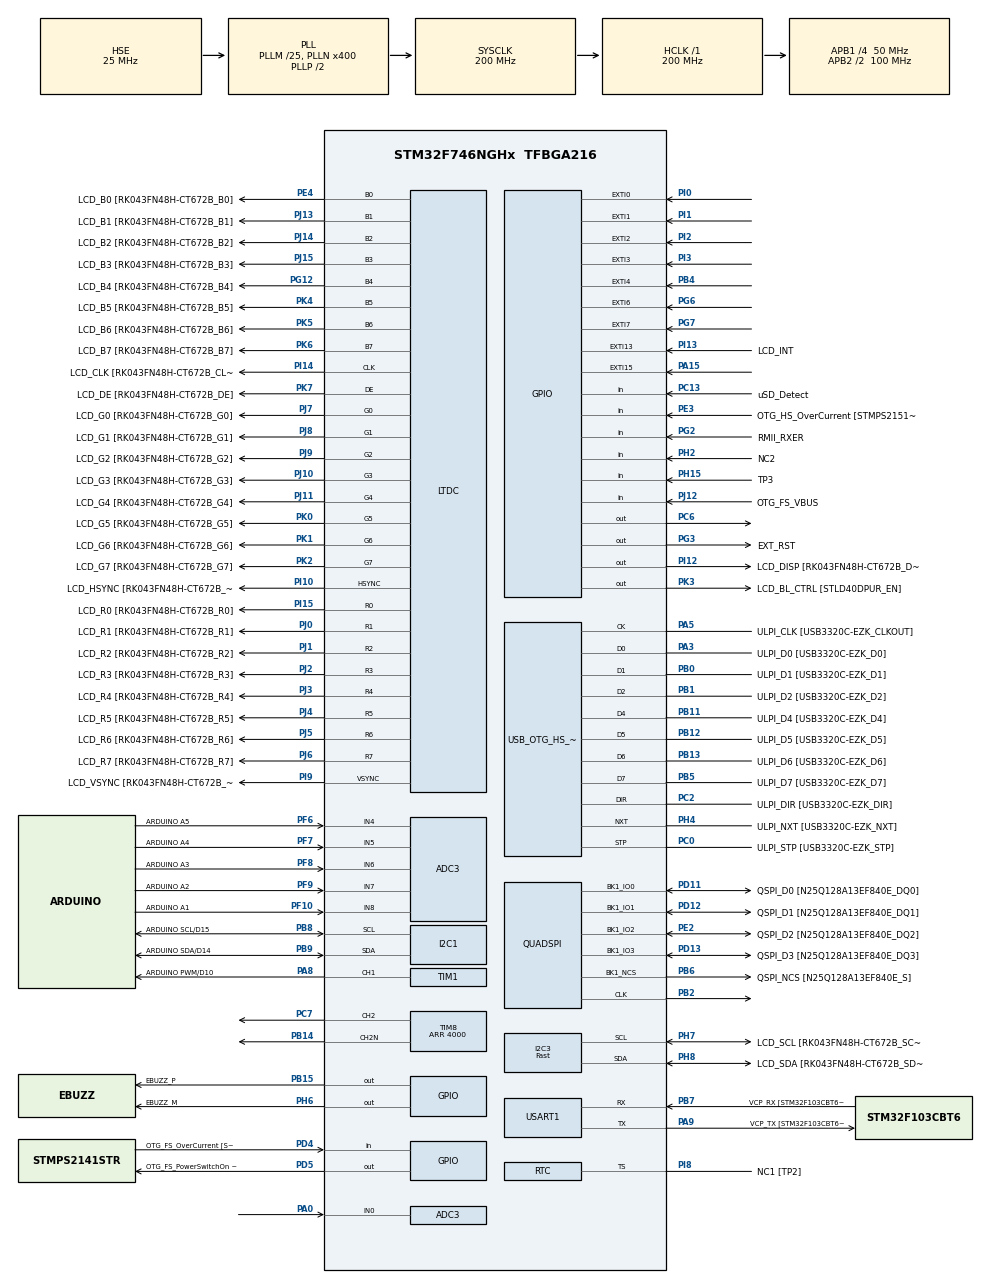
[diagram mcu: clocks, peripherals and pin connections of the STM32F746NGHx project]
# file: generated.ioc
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VP_TIM5_VS_ClockSourceINT.Mode=Internal
Dma.ADC3.0.FIFOMode=DMA_FIFOMODE_DISABLE
PD12.GPIO_Label=QSPI_D1 [N25Q128A13EF840E_DQ1]
NVIC.I2C1_EV_IRQn=true\:0\:0\:false\:false\:true\:true\:true
SH.FMC_A0.0=FMC_A0
PH15.GPIO_Label=TP3
NVIC.TIM6_DAC_IRQn=true\:0\:0\:false\:false\:true\:false\:true
PG8.Signal=FMC_SDCLK
PG0.Signal=FMC_A10
PI15.GPIO_Label=LCD_R0 [RK043FN48H-CT672B_R0]
PK1.Signal=LTDC_G6
SH.FMC_D5_DA5.0=FMC_D5
PF10.GPIO_PuPd=GPIO_NOPULL
SH.FMC_D9_DA9.0=FMC_D9
NVIC.EXTI1_IRQn=true\:0\:0\:false\:false\:true\:true\:true
PG15.GPIO_Label=FMC_SDNCAS [MT48LC4M32B2B5-6A_CAS]
PF7.Signal=ADC3_IN5
NVIC.DMA2D_IRQn=true\:0\:0\:false\:false\:true\:true\:true
RCC.PLL48CLockSelection=RCC_CLK48SOURCE_PLLSAIP
SH.FMC_SDNWE.0=FMC_SDNWE
PA15.GPIO_ModeDefaultEXTI=GPIO_MODE_IT_RISING_FALLING
PH9.Signal=DCMI_D0
SH.FMC_D11_DA11.0=FMC_D11
PJ5.Mode=RGB888
RCC.APB2TimFreq_Value=200000000
PB6.Signal=QUADSPI_BK1_NCS
Dma.ADC3.0.Direction=DMA_PERIPH_TO_MEMORY
PC7.Signal=S_TIM8_CH2
PD0.Signal=FMC_D2_DA2
ADC3.ScanConvMode=ADC_SCAN_ENABLE
PD8.Signal=FMC_D13_DA13
PE1.Signal=FMC_NBL1
NVIC.EXTI15_10_IRQn=true\:0\:0\:false\:false\:true\:true\:true
PF1.GPIO_Label=FMC_A1 [MT48LC4M32B2B5-6A_A1]
PI4.GPIO_Label=SAI2_MCLKA [WM8994ECS/R_MCLK1]
PK4.GPIO_Label=LCD_B5 [RK043FN48H-CT672B_B5]
PD1.GPIO_Label=FMC_D3 [MT48LC4M32B2B5-6A_DQ3]
PB12.GPIO_Label=ULPI_D5 [USB3320C-EZK_D5]
PJ14.Mode=RGB888
PF12.GPIO_Label=FMC_A6 [MT48LC4M32B2B5-6A_A6]
LTDC.PixelFormat_L0=LTDC_PIXEL_FORMAT_RGB565
PC4.GPIO_Label=RMII_RXD0 [LAN8742A-CZ-TR_RXD0]
TIM1.Channel-PWM\ Generation1\ CH1=TIM_CHANNEL_1
PE9.Signal=FMC_D6_DA6
SH.FMC_A2.0=FMC_A2
PB14.Mode=PWM Generation2 CH2 CH2N
PB1.GPIO_Label=ULPI_D2 [USB3320C-EZK_D2]
PE4.GPIO_Label=LCD_B0 [RK043FN48H-CT672B_B0]
PG4.GPIO_Label=FMC_BA0 [MT48LC4M32B2B5-6A_BA0]
PA8.Signal=S_TIM1_CH1
SH.FMC_D1_DA1.0=FMC_D1
LTDC.HSync=41
PJ14.Signal=LTDC_B2
PB9.Signal=I2C1_SDA
Mcu.Package=TFBGA216
PB1.Signal=USB_OTG_HS_ULPI_D2
NVIC.TimeBase=TIM6_DAC_IRQn
PD12.Signal=QUADSPI_BK1_IO1
NVIC.TimeBaseIP=TIM6
PB9.GPIO_PuPd=GPIO_NOPULL
PA10.Signal=USB_OTG_FS_ID
VP_RTC_VS_RTC_Calendar.Mode=RTC_Calendar
PE12.GPIO_Label=FMC_D9 [MT48LC4M32B2B5-6A_DQ9]
ADC3.DMAContinuousRequests=ENABLE
RCC.APB2CLKDivider=RCC_HCLK_DIV2
NVIC.EXTI2_IRQn=true\:0\:0\:false\:false\:true\:true\:true
LTDC.VSync=10
RCC.APB1TimFreq_Value=100000000
Dma.ADC3.0.Instance=DMA2_Stream0
PC14/OSC32_IN.GPIO_Label=RCC_OSC32_IN
PF10.Mode=IN8
PB13.Mode=Host_HS
PJ13.Mode=RGB888
PH8.Mode=I2C
PF9.GPIO_PuPd=GPIO_NOPULL
PA4.GPIO_Label=DCMI_HSYNC
PA8.GPIO_Speed=GPIO_SPEED_FREQ_LOW
PD15.Signal=FMC_D1_DA1
PJ1.GPIO_Label=LCD_R2 [RK043FN48H-CT672B_R2]
PG12.Signal=LTDC_B4
PA5.Mode=Host_HS
PK4.Signal=LTDC_B5
SH.FMC_A4.0=FMC_A4
PI0.GPIO_ModeDefaultEXTI=GPIO_MODE_IT_RISING_FALLING
ADC3.Channel-IN0=ADC_CHANNEL_0
ADC3.Channel-IN5=ADC_CHANNEL_5
ADC3.Channel-IN4=ADC_CHANNEL_4
PI13.GPIO_ModeDefaultEXTI=GPIO_MODE_IT_RISING_FALLING
ADC3.Channel-IN7=ADC_CHANNEL_7
PG5.Signal=FMC_A15_BA1
ADC3.Channel-IN6=ADC_CHANNEL_6
PC13.Signal=GPIO_Input
SH.FMC_D10_DA10.0=FMC_D10
ADC3.Channel-IN8=ADC_CHANNEL_8
PD3.Signal=DCMI_D5
PI10.Mode=RGB888
PC2.Signal=USB_OTG_HS_ULPI_DIR
PI12.Signal=GPIO_Output
PJ11.Signal=LTDC_G4
RCC.PLLSAIRDiv=RCC_PLLSAIDIVR_8
PF8.GPIO_Label=ARDUINO A3
LTDC.ImageWidth_L0=480
PD10.Signal=FMC_D15_DA15
PJ6.Mode=RGB888
PA3.Mode=Host_HS
TIM1.AutoReloadPreload=TIM_AUTORELOAD_PRELOAD_ENABLE
PB8.GPIO_Label=ARDUINO SCL/D15
PJ8.GPIO_Label=LCD_G1 [RK043FN48H-CT672B_G1]
PJ3.Signal=LTDC_R4
PI8.GPIO_Label=NC1 [TP2]
PA8.GPIO_Label=ARDUINO PWM/D10
PE8.GPIO_Label=FMC_D5 [MT48LC4M32B2B5-6A_DQ5]
PH11.GPIO_Label=DCMI_D2
VP_TIM8_VS_ClockSourceINT.Mode=Internal
PJ11.GPIO_Label=LCD_G4 [RK043FN48H-CT672B_G4]
PB14.Signal=TIM8_CH2N
PA5.Signal=USB_OTG_HS_ULPI_CK
PF10.GPIO_Mode=GPIO_MODE_ANALOG
PJ4.GPIO_Label=LCD_R5 [RK043FN48H-CT672B_R5]
PE1.GPIO_Label=FMC_NBL1 [MT48LC4M32B2B5-6A_DQM1]
PK7.GPIO_Label=LCD_DE [RK043FN48H-CT672B_DE]
PI7.Signal=SAI2_FS_A
SH.FMC_A6.0=FMC_A6
PE14.Signal=FMC_D11_DA11
PB15.GPIO_Label=EBUZZ_P
PI2.Signal=GPXTI2
PF4.GPIO_Label=FMC_A4 [MT48LC4M32B2B5-6A_A4]
PA1.GPIO_Label=RMII_REF_CLK [LAN8742A-CZ-TR_REFCLK0]
PF13.Signal=FMC_A7
PJ15.GPIO_Label=LCD_B3 [RK043FN48H-CT672B_B3]
Dma.ADC3.0.PeriphDataAlignment=DMA_PDATAALIGN_HALFWORD
TIM8.Period=4000
ADC3.Rank-1\#ChannelRegularConversion=2
PJ15.Mode=RGB888
PA5.GPIO_Label=ULPI_CLK [USB3320C-EZK_CLKOUT]
PK4.Mode=RGB888
PC12.GPIO_Label=SDMMC_CK
PE5.GPIO_Label=DCMI_D6
PJ8.Signal=LTDC_G1
PJ0.GPIO_Label=LCD_R1 [RK043FN48H-CT672B_R1]
ProjectManager.HeapSize=0x200
PB1.Mode=Host_HS
ADC3.EOCSelection=ADC_EOC_SEQ_CONV
PH6.Signal=GPIO_Output
NVIC.PriorityGroup=NVIC_PRIORITYGROUP_4
PF0.GPIO_Label=FMC_A0 [MT48LC4M32B2B5-6A_A0]
PE3.Signal=GPIO_Input
PJ4.Mode=RGB888
PC15/OSC32_OUT.Signal=RCC_OSC32_OUT
PF4.Signal=FMC_A4
PD2.Signal=SDMMC1_CMD
Mcu.Family=STM32F7
LTDC.BlendingFactor1_L0=LTDC_BLENDING_FACTOR1_PAxCA
PK3.Signal=GPIO_Output
SH.FMC_A8.0=FMC_A8
PC15/OSC32_OUT.GPIO_Label=RCC_OSC32_OUT
PH14.Signal=DCMI_D4
PH10.Signal=DCMI_D1
SH.FMC_D14_DA14.0=FMC_D14
ADC3.Channel-3\#ChannelRegularConversion=ADC_CHANNEL_6
PG2.Signal=GPIO_Input
PE11.GPIO_Label=FMC_D8 [MT48LC4M32B2B5-6A_DQ8]
PD0.GPIO_Label=FMC_D2 [MT48LC4M32B2B5-6A_DQ2]
PC14/OSC32_IN.Mode=LSE-External-Oscillator
SH.FMC_A14_BA0.0=FMC_BA0
SH.FMC_A11.0=FMC_A11
PB13.GPIO_Label=ULPI_D6 [USB3320C-EZK_D6]
PG5.GPIO_Label=FMC_BA1 [MT48LC4M32B2B5-6A_BA1]
PB15.Signal=GPIO_Output
ADC3.Channel-0\#ChannelRegularConversion=ADC_CHANNEL_0
VP_RTC_VS_RTC_Alarm_B_Intern.Mode=Alarm B
PG15.Signal=FMC_SDNCAS
PG11.Signal=ETH_TX_EN
PJ5.GPIO_Label=LCD_R6 [RK043FN48H-CT672B_R6]
PJ14.GPIO_Label=LCD_B2 [RK043FN48H-CT672B_B2]
ADC3.Rank-2\#ChannelRegularConversion=3
PD13.Signal=QUADSPI_BK1_IO3
PJ2.Signal=LTDC_R3
SH.FMC_NBL1.0=FMC_NBL1
LTDC.WindowX1_L0=480
PI9.Mode=RGB888
PK2.Mode=RGB888
PA9.GPIO_Mode=GPIO_MODE_AF_PP
RCC.HSE_VALUE=25000000
PF7.GPIO_Mode=GPIO_MODE_ANALOG
PI14.Mode=RGB888
PF9.Mode=IN7
PF8.GPIO_PuPd=GPIO_NOPULL
PA14.Mode=Serial_Wire
PH7.GPIO_Label=LCD_SCL [RK043FN48H-CT672B_SCL]
PJ7.GPIO_Label=LCD_G0 [RK043FN48H-CT672B_G0]
PF11.Signal=FMC_SDNRAS
PC11.GPIO_Label=SDMMC_D3
PB5.Mode=Host_HS
PG6.GPIO_ModeDefaultEXTI=GPIO_MODE_IT_RISING_FALLING
PJ12.GPIO_Label=OTG_FS_VBUS
PB7.Signal=USART1_RX
TIM8.OC2Preload_PWM=DISABLE
PI8.Mode=Timestamp enabled - Input Enabled to TS
PB7.GPIO_Label=VCP_RX [STM32F103CBT6_PA2]
PD13.GPIO_Label=QSPI_D3 [N25Q128A13EF840E_DQ3]
PA6.Signal=DCMI_PIXCLK
PB12.Mode=Host_HS
PD5.GPIO_Label=OTG_FS_PowerSwitchOn [STMPS2141STR_EN]
PA15.Signal=GPXTI15
PF8.Signal=ADC3_IN6
PG0.GPIO_Label=FMC_A10 [MT48LC4M32B2B5-6A_A10]
I2C3.Timing=0x00401959
PB5.GPIO_Label=ULPI_D7 [USB3320C-EZK_D7]
PG11.GPIO_Label=RMII_TX_EN [LAN8742A-CZ-TR_TXEN]
PD3.GPIO_Label=DCMI_D5
PC5.Signal=ETH_RXD1
PE7.Signal=FMC_D4_DA4
TIM8.OCMode_PWM-PWM\ Generation2\ CH2\ CH2N=TIM_OCMODE_COMBINED_PWM1
Dma.Request0=ADC3
PF3.GPIO_Label=FMC_A3 [MT48LC4M32B2B5-6A_A3]
PI15.Mode=RGB888
PE2.GPIO_Label=QSPI_D2 [N25Q128A13EF840E_DQ2]
VP_TIM3_VS_ClockSourceINT.Mode=Internal
PB4.Signal=GPXTI4
PG2.GPIO_Label=RMII_RXER
PA3.Signal=USB_OTG_HS_ULPI_D0
PK1.Mode=RGB888
PK6.Signal=LTDC_B7
ADC3.SamplingTime-3\#ChannelRegularConversion=ADC_SAMPLETIME_56CYCLES
NVIC.LTDC_IRQn=true\:0\:0\:false\:false\:true\:true\:true
PD15.GPIO_Label=FMC_D1 [MT48LC4M32B2B5-6A_DQ1]
LTDC.WindowY1_L0=272
PG7.Signal=GPXTI7
PJ8.Mode=RGB888
PH12.GPIO_Label=DCMI_D3
PC11.Signal=SDMMC1_D3
PI14.Signal=LTDC_CLK
PC8.Signal=SDMMC1_D0
PC2.Mode=Host_HS
PE14.GPIO_Label=FMC_D11 [MT48LC4M32B2B5-6A_DQ11]
PD9.Signal=FMC_D14_DA14
PA9.GPIO_PuPd=GPIO_NOPULL
PA12.GPIO_Label=OTG_FS_P
PD8.GPIO_Label=FMC_D13 [MT48LC4M32B2B5-6A_DQ13]
PG8.GPIO_Label=FMC_SDCLK [MT48LC4M32B2B5-6A_CLK]
USART1.VirtualMode-Asynchronous=VM_ASYNC
PA13.Signal=SYS_JTMS-SWDIO
PA9.Mode=Asynchronous
ADC3.SamplingTime-0\#ChannelRegularConversion=ADC_SAMPLETIME_56CYCLES
SH.S_TIM1_CH1.0=TIM1_CH1,PWM Generation1 CH1
PF6.Signal=ADC3_IN4
PB10.GPIO_Label=ULPI_D3 [USB3320C-EZK_D3]
SH.FMC_D13_DA13.0=FMC_D13
PH8.Signal=I2C3_SDA
PB9.Mode=I2C
RCC.USBFreq_Value=48000000
PF9.GPIO_Label=ARDUINO A2
PD10.GPIO_Label=FMC_D15 [MT48LC4M32B2B5-6A_DQ15]
PA1.Signal=ETH_REF_CLK
PK5.Mode=RGB888
board=STM32F746G-DISCO
PG12.Mode=RGB888
RCC.VCOOutputFreq_Value=400000000
PI9.Signal=LTDC_VSYNC
PH4.GPIO_Label=ULPI_NXT [USB3320C-EZK_NXT]
PI13.GPIO_Label=LCD_INT
PI4.Signal=SAI2_MCLK_A
PC1.GPIO_Label=RMII_MDC [LAN8742A-CZ-TR_MDC]
SH.FMC_D12_DA12.0=FMC_D12
PF15.GPIO_Label=FMC_A9 [MT48LC4M32B2B5-6A_A9]
PF1.Signal=FMC_A1
PF8.GPIO_Mode=GPIO_MODE_ANALOG
PJ0.Signal=LTDC_R1
PE0.Signal=FMC_NBL0
RTC.Alarm-Alarm\ A=RTC_ALARM_A
PE7.GPIO_Label=FMC_D4 [MT48LC4M32B2B5-6A_DQ4]
PE12.Signal=FMC_D9_DA9
RCC.SYSCLKFreq_VALUE=200000000
PB2.Mode=Single Bank 1
PJ5.Signal=LTDC_R6
NVIC.EXTI9_5_IRQn=true\:0\:0\:false\:false\:true\:true\:true
PD11.Mode=Single Bank 1
RCC.HSI_VALUE=16000000
PA8.GPIO_PuPd=GPIO_NOPULL
PH0/OSC_IN.GPIO_Label=OSC_25M [NZ2520SB-25.00M_OUT]
PF9.GPIO_Mode=GPIO_MODE_ANALOG
RCC.PLLQ=9
PH3.Signal=FMC_SDNE0
RCC.PLLM=25
RCC.PLLN=400
PA9.GPIO_Speed=GPIO_SPEED_FREQ_LOW
PB8.GPIO_Speed=GPIO_SPEED_FREQ_LOW
PJ2.GPIO_Label=LCD_R3 [RK043FN48H-CT672B_R3]
VP_CRC_VS_CRC.Mode=CRC_Activate
LTDC.ImageHeight_L0=272
RCC.PLLI2SN=100
PB12.Signal=USB_OTG_HS_ULPI_D5
PJ13.Signal=LTDC_B1
PK1.GPIO_Label=LCD_G6 [RK043FN48H-CT672B_G6]
PA3.GPIO_Label=ULPI_D0 [USB3320C-EZK_D0]
PI12.PinState=GPIO_PIN_SET
SH.FMC_D7_DA7.0=FMC_D7
RTC.Alarm_B-Alarm\ B=RTC_ALARM_B
PK5.Signal=LTDC_B6
VP_SYS_VS_tim6.Mode=TIM6
Dma.ADC3.0.Priority=DMA_PRIORITY_LOW
PJ9.Mode=RGB888
PH12.Signal=DCMI_D3
PK0.Mode=RGB888
PG4.Signal=FMC_A14_BA0
PC12.Signal=SDMMC1_CK
PA14.GPIO_Label=SWCLK
PH6.GPIO_Label=EBUZZ_M
PK6.GPIO_Label=LCD_B7 [RK043FN48H-CT672B_B7]
VP_RTC_VS_RTC_Activate.Mode=RTC_Enabled
PI6.GPIO_Label=SAI2_SDA [WM8994ECS/R_DACDAT1]
PB6.GPIO_Label=QSPI_NCS [N25Q128A13EF840E_S]
PJ6.GPIO_Label=LCD_R7 [RK043FN48H-CT672B_R7]
PB13.Signal=USB_OTG_HS_ULPI_D6
PG13.Signal=ETH_TXD0
PE6.GPIO_Label=DCMI_D7
PF6.GPIO_Label=ARDUINO A5
RCC.SYSCLKSource=RCC_SYSCLKSOURCE_PLLCLK
PJ10.Signal=LTDC_G3
SH.FMC_A15_BA1.0=FMC_BA1
PB7.GPIO_Mode=GPIO_MODE_AF_PP
PJ13.GPIO_Label=LCD_B1 [RK043FN48H-CT672B_B1]
PH5.Signal=FMC_SDNWE
PE2.Mode=Single Bank 1
PD4.Signal=GPIO_Input
PB6.Mode=Single Bank 1
PH1/OSC_OUT.Signal=RCC_OSC_OUT
PC3.Signal=FMC_SDCKE0
PE5.Signal=DCMI_D6
PF10.GPIO_Label=ARDUINO A1
PH10.GPIO_Label=DCMI_D1
PB2.Signal=QUADSPI_CLK
ADC3.SamplingTime-2\#ChannelRegularConversion=ADC_SAMPLETIME_56CYCLES
Dma.ADC3.0.PeriphInc=DMA_PINC_DISABLE
PK7.Mode=RGB888
PJ2.Mode=RGB888
PI6.Signal=SAI2_SD_A
PI3.Signal=GPXTI3
ADC3.ContinuousConvMode=ENABLE
PE2.Signal=QUADSPI_BK1_IO2
PF8.Mode=IN6
PF3.Signal=FMC_A3
ADC3.Channel-2\#ChannelRegularConversion=ADC_CHANNEL_7
NVIC.I2C1_ER_IRQn=true\:0\:0\:false\:false\:true\:true\:true
PE10.Signal=FMC_D7_DA7
ADC3.Rank-4\#ChannelRegularConversion=5
VP_TIM1_VS_ClockSourceINT.Mode=Internal
RCC.SDMMCClockSelection=RCC_SDMMC1CLKSOURCE_CLK48
PI3.GPIO_ModeDefaultEXTI=GPIO_MODE_IT_RISING_FALLING
PJ4.Signal=LTDC_R5
SH.FMC_A1.0=FMC_A1
PH2.Signal=GPIO_Input
SH.FMC_SDCLK.0=FMC_SDCLK
PF14.Signal=FMC_A8
VP_DMA2D_VS_DMA2D.Mode=DMA2D_Activate
PF6.GPIO_Mode=GPIO_MODE_ANALOG
TIM1.Period=2000
PE10.GPIO_Label=FMC_D7 [MT48LC4M32B2B5-6A_DQ7]
PJ1.Mode=RGB888
SH.FMC_D3_DA3.0=FMC_D3
PI10.GPIO_Label=LCD_HSYNC [RK043FN48H-CT672B_HSYNC]
PB7.GPIO_PuPd=GPIO_NOPULL
NVIC.EXTI4_IRQn=true\:0\:0\:false\:false\:true\:true\:true
PK3.PinState=GPIO_PIN_SET
PH15.Signal=GPIO_Input
PI1.GPIO_ModeDefaultEXTI=GPIO_MODE_IT_RISING_FALLING
PD9.GPIO_Label=FMC_D14 [MT48LC4M32B2B5-6A_DQ14]
PG9.Signal=DCMI_VSYNC
PA9.GPIO_Label=VCP_TX [STM32F103CBT6_PA3]
PB8.GPIO_PuPd=GPIO_NOPULL
PC6.Signal=GPIO_Output
PB11.GPIO_Label=ULPI_D4 [USB3320C-EZK_D4]
PD7.Signal=SPDIFRX_IN0
PD1.Signal=FMC_D3_DA3
PA11.GPIO_Label=OTG_FS_N
PF14.GPIO_Label=FMC_A8 [MT48LC4M32B2B5-6A_A8]
PC0.Signal=USB_OTG_HS_ULPI_STP
RCC.APB1CLKDivider=RCC_HCLK_DIV4
PF13.GPIO_Label=FMC_A7 [MT48LC4M32B2B5-6A_A7]
PG13.GPIO_Label=RMII_TXD0 [LAN8742A-CZ-TR_TXD0]
SH.S_TIM8_CH2.0=TIM8_CH2,PWM Generation2 CH2 CH2N
PG10.Signal=SAI2_SD_B
SH.FMC_A3.0=FMC_A3
PJ7.Signal=LTDC_G0
PB11.Mode=Host_HS
SH.FMC_D15_DA15.0=FMC_D15
PA9.Signal=USART1_TX
I2C1.Timing=0x00C0EAFF
ADC3.NbrOfConversion=5
PE9.GPIO_Label=FMC_D6 [MT48LC4M32B2B5-6A_DQ6]
PB10.Signal=USB_OTG_HS_ULPI_D3
PJ15.Signal=LTDC_B3
PH9.GPIO_Label=DCMI_D0
TIM8.AutoReloadPreload=TIM_AUTORELOAD_PRELOAD_ENABLE
PI9.GPIO_Label=LCD_VSYNC [RK043FN48H-CT672B_VSYNC]
PA8.GPIO_ModeDefaultPP=GPIO_MODE_AF_PP
PE15.Signal=FMC_D12_DA12
PE8.Signal=FMC_D5_DA5
PI1.Signal=GPXTI1
PG14.GPIO_Label=RMII_TXD1 [LAN8742A-CZ-TR_TXD1]
PA13.Mode=Serial_Wire
SH.FMC_SDNCAS.0=FMC_SDNCAS
ADC3.Channel-1\#ChannelRegularConversion=ADC_CHANNEL_8
PH4.Mode=Host_HS
PF7.GPIO_PuPd=GPIO_NOPULL
PH14.GPIO_Label=DCMI_D4
PA4.Signal=DCMI_HSYNC
PB5.Signal=USB_OTG_HS_ULPI_D7
PD12.Mode=Single Bank 1
PE13.GPIO_Label=FMC_D10 [MT48LC4M32B2B5-6A_DQ10]
PD11.Signal=QUADSPI_BK1_IO0
SH.FMC_A5.0=FMC_A5
LTDC.Alpha_L0=255
PA11.Signal=USB_OTG_FS_DM
PK3.GPIO_Label=LCD_BL_CTRL [STLD40DPUR_EN]
Dma.ADC3.0.Mode=DMA_CIRCULAR
PF6.Mode=IN4
PF9.Signal=ADC3_IN7
PJ10.Mode=RGB888
PB8.Mode=I2C
PF6.GPIO_PuPd=GPIO_NOPULL
PC3.GPIO_Label=FMC_SDCKE0 [MT48LC4M32B2B5-6A_CKE]
PG3.GPIO_Label=EXT_RST
PB0.Signal=USB_OTG_HS_ULPI_D1
PC1.Signal=ETH_MDC
PG10.GPIO_Label=SAI2_SDB [WM8994ECS/R_ADCDAT1]
PD2.GPIO_Label=SDMMC_CMD
PH2.GPIO_Label=NC2
I2C3.I2C_Speed_Mode=I2C_Fast
PK7.Signal=LTDC_DE
RCC.CortexFreq_Value=200000000
PG6.Signal=GPXTI6
PB4.GPIO_ModeDefaultEXTI=GPIO_MODE_IT_RISING_FALLING
LTDC.HBP=13
PC10.Signal=SDMMC1_D2
SH.FMC_NBL0.0=FMC_NBL0
NVIC.EXTI3_IRQn=true\:0\:0\:false\:false\:true\:true\:true
PC0.GPIO_Label=ULPI_STP [USB3320C-EZK_STP]
SH.FMC_D6_DA6.0=FMC_D6
PA0/WKUP.Signal=ADCx_IN0
PB0.GPIO_Label=ULPI_D1 [USB3320C-EZK_D1]
PH5.GPIO_Label=FMC_SDNME [MT48LC4M32B2B5-6A_WE]
PI5.GPIO_Label=SAI2_SCKA [WM8994ECS/R_BCLK1]
PC13.GPIO_Label=uSD_Detect
PK5.GPIO_Label=LCD_B6 [RK043FN48H-CT672B_B6]
PB11.Signal=USB_OTG_HS_ULPI_D4
PI14.GPIO_Label=LCD_CLK [RK043FN48H-CT672B_CLK]
VP_RTC_VS_RTC_Alarm_A_Intern.Mode=Alarm A
ProjectManager.StackSize=0x400
ADC3.SamplingTime-4\#ChannelRegularConversion=ADC_SAMPLETIME_56CYCLES
PJ6.Signal=LTDC_R7
SH.FMC_A7.0=FMC_A7
PA12.Signal=USB_OTG_FS_DP
TIM8.Channel-PWM\ Generation2\ CH2\ CH2N=TIM_CHANNEL_2
PH0/OSC_IN.Mode=HSE-External-Oscillator
PD11.GPIO_Label=QSPI_D0 [N25Q128A13EF840E_DQ0]
RCC.HCLKFreq_Value=200000000
PF11.GPIO_Label=FMC_SDNRAS [MT48LC4M32B2B5-6A_RAS]
PF12.Signal=FMC_A6
NVIC.DMA2_Stream0_IRQn=true\:0\:0\:false\:false\:true\:false\:true
PI13.Signal=GPXTI13
Dma.ADC3.0.MemDataAlignment=DMA_MDATAALIGN_HALFWORD
SH.FMC_A10.0=FMC_A10
RCC.AHBFreq_Value=200000000
ADC3.SamplingTime-1\#ChannelRegularConversion=ADC_SAMPLETIME_56CYCLES
SH.FMC_D8_DA8.0=FMC_D8
PI8.Signal=RTC_TS
PG7.GPIO_ModeDefaultEXTI=GPIO_MODE_IT_RISING_FALLING
SH.FMC_D2_DA2.0=FMC_D2
PE13.Signal=FMC_D10_DA10
PF7.GPIO_Label=ARDUINO A4
PI5.Signal=SAI2_SCK_A
PK6.Mode=RGB888
PI0.Signal=GPXTI0
PA10.GPIO_Label=OTG_FS_ID
SH.ADCx_IN0.1=ADC2_IN0
Dma.ADC3.0.MemInc=DMA_MINC_ENABLE
LTDC.HFP=32
LTDC.BlendingFactor2_L0=LTDC_BLENDING_FACTOR2_PAxCA
SH.ADCx_IN0.0=ADC3_IN0,IN0
PE4.Mode=RGB888
SH.FMC_SDNRAS.0=FMC_SDNRAS
LTDC.ActiveW=480
PE4.Signal=LTDC_B0
PH1/OSC_OUT.Mode=HSE-External-Oscillator
PD7.GPIO_Label=SPDIF_RX0 [74LVC1G04SE_4]
PH7.Mode=I2C
PJ0.Mode=RGB888
PJ9.Signal=LTDC_G2
SH.FMC_D0_DA0.0=FMC_D0
PJ12.Signal=GPIO_Input
PC14/OSC32_IN.Signal=RCC_OSC32_IN
ADC3.Channel=ADC_CHANNEL_7
PK0.GPIO_Label=LCD_G5 [RK043FN48H-CT672B_G5]
PA2.GPIO_Label=RMII_MDIO [LAN8742A-CZ-TR_MDIO]
PF5.GPIO_Label=FMC_A5 [MT48LC4M32B2B5-6A_A5]
SH.FMC_A9.0=FMC_A9
PJ1.Signal=LTDC_R2
SH.FMC_D4_DA4.0=FMC_D4
PI12.GPIO_Label=LCD_DISP [RK043FN48H-CT672B_DISP] 
PE0.GPIO_Label=FMC_NBL0 [MT48LC4M32B2B5-6A_DQM0]
RCC.PLLSAIN=384
PH3.GPIO_Label=FMC_SDNE0 [MT48LC4M32B2B5-6A_CS]
PF5.Signal=FMC_A5
RCC.PLLSAIP=RCC_PLLSAIP_DIV8
RCC.PLLSAIR=5
PH7.Signal=I2C3_SCL
PB9.GPIO_Speed=GPIO_SPEED_FREQ_LOW
PJ3.GPIO_Label=LCD_R4 [RK043FN48H-CT672B_R4]
PK2.GPIO_Label=LCD_G7 [RK043FN48H-CT672B_G7]
PJ7.Mode=RGB888
PF0.Signal=FMC_A0
PC2.GPIO_Label=ULPI_DIR [USB3320C-EZK_DIR]
PB7.GPIO_Speed=GPIO_SPEED_FREQ_LOW
PB3.GPIO_Label=SWO
RCC.PLLSourceVirtual=RCC_PLLSOURCE_HSE
PK2.Signal=LTDC_G7
LTDC.FBStartAdress_L0=0xC0000000
PB9.GPIO_Label=ARDUINO SDA/D14
PC10.GPIO_Label=SDMMC_D2
PH11.Signal=DCMI_D2
PG3.Signal=GPIO_Output
PG1.Signal=FMC_A11
PI2.GPIO_ModeDefaultEXTI=GPIO_MODE_IT_RISING_FALLING
PC4.Signal=ETH_RXD0
PI10.Signal=LTDC_HSYNC
PD5.Signal=GPIO_Output
ADC3.Rank-3\#ChannelRegularConversion=4
PC0.Mode=Host_HS
PJ11.Mode=RGB888
PF7.Mode=IN5
PH8.GPIO_Label=LCD_SDA [RK043FN48H-CT672B_SDA]
PE15.GPIO_Label=FMC_D12 [MT48LC4M32B2B5-6A_DQ12]
PH4.Signal=USB_OTG_HS_ULPI_NXT
ProjectManager.TargetToolchain=Makefile
ADC3.Channel-4\#ChannelRegularConversion=ADC_CHANNEL_5
LTDC.ActiveH=272
PJ9.GPIO_Label=LCD_G2 [RK043FN48H-CT672B_G2]
PD13.Mode=Single Bank 1
PF2.Signal=FMC_A2
PE11.Signal=FMC_D8_DA8
PK0.Signal=LTDC_G5
PG9.GPIO_Label=DCMI_VSYNC
PG14.Signal=ETH_TXD1
PJ10.GPIO_Label=LCD_G3 [RK043FN48H-CT672B_G3]
PB0.Mode=Host_HS
TIM8.DeadTime=10
PG1.GPIO_Label=FMC_A11 [MT48LC4M32B2B5-6A_A11]
PB9.GPIO_Mode=GPIO_MODE_AF_OD
PJ3.Mode=RGB888
PH0/OSC_IN.Signal=RCC_OSC_IN
RCC.APB2Freq_Value=100000000
LTDC.Layers=0
VP_TIM2_VS_ClockSourceINT.Mode=Internal
PD4.GPIO_Label=OTG_FS_OverCurrent [STMPS2141STR_Fault]
PF10.Signal=ADC3_IN8
PI7.GPIO_Label=SAI2_FSA [WM8994ECS/R_LRCLK1]
PF15.Signal=FMC_A9
PD14.GPIO_Label=FMC_D0 [MT48LC4M32B2B5-6A_DQ0]
PD5.PinState=GPIO_PIN_SET
PE6.Signal=DCMI_D7
Mcu.Name=STM32F746NGHx
PA13.GPIO_Label=SWDIO
PA2.Signal=ETH_MDIO
PD14.Signal=FMC_D0_DA0
PB3.Signal=SYS_JTDO-SWO
NVIC.EXTI0_IRQn=true\:0\:0\:false\:false\:true\:true\:true
PA7.GPIO_Label=RMII_CRS_DV [LAN8742A-CZ-TR_CRS_DV]
PC5.GPIO_Label=RMII_RXD1 [LAN8742A-CZ-TR_RXD1]
PC15/OSC32_OUT.Mode=LSE-External-Oscillator
PB7.Mode=Asynchronous
PA14.Signal=SYS_JTCK-SWCLK
PG12.GPIO_Label=LCD_B4 [RK043FN48H-CT672B_B4]
PK3.GPIO_Speed=GPIO_SPEED_FREQ_LOW
PI15.Signal=LTDC_R0
PB8.Signal=I2C1_SCL
PE3.GPIO_Label=OTG_HS_OverCurrent [STMPS2151STR_FAULT]
PC9.Signal=SDMMC1_D1
PB8.GPIO_Mode=GPIO_MODE_AF_OD
RCC.APB1Freq_Value=50000000
PA7.Signal=ETH_CRS_DV
PF2.GPIO_Label=FMC_A2 [MT48LC4M32B2B5-6A_A2]

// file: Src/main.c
/* USER CODE BEGIN Header */
/**
  ******************************************************************************
  * @file           : main.c
  * @brief          : Main program body
  ******************************************************************************
  * @attention
  *
  * <h2><center>&copy; Copyright (c) 2020 STMicroelectronics.
  * All rights reserved.</center></h2>
  *
  * This software component is licensed by ST under BSD 3-Clause license,
  * the "License"; You may not use this file except in compliance with the
  * License. You may obtain a copy of the License at:
  *                        opensource.org/licenses/BSD-3-Clause
  *
  ******************************************************************************
  */
/* USER CODE END Header */

#include "main.h"

/* USER CODE BEGIN Includes */
#include "demo.h"
/* USER CODE END Includes */

ADC_HandleTypeDef hadc3;
DMA_HandleTypeDef hdma_adc3;

CRC_HandleTypeDef hcrc;

DMA2D_HandleTypeDef hdma2d;

I2C_HandleTypeDef hi2c1;
I2C_HandleTypeDef hi2c3;

LTDC_HandleTypeDef hltdc;

QSPI_HandleTypeDef hqspi;

RTC_HandleTypeDef hrtc;

TIM_HandleTypeDef htim1;
TIM_HandleTypeDef htim2;
TIM_HandleTypeDef htim3;
TIM_HandleTypeDef htim5;
TIM_HandleTypeDef htim8;

UART_HandleTypeDef huart1;

void SystemClock_Config(void);
static void MX_GPIO_Init(void);
static void MX_DMA_Init(void);
static void MX_ADC3_Init(void);
static void MX_CRC_Init(void);
static void MX_DMA2D_Init(void);
static void MX_I2C1_Init(void);
static void MX_I2C3_Init(void);
static void MX_LTDC_Init(void);
static void MX_QUADSPI_Init(void);
static void MX_RTC_Init(void);
static void MX_TIM1_Init(void);
static void MX_TIM2_Init(void);
static void MX_TIM3_Init(void);
static void MX_TIM5_Init(void);
static void MX_TIM8_Init(void);
static void MX_USART1_UART_Init(void);

int main(void)
{
  /* USER CODE BEGIN 1 */
    (DBGMCU)->APB1FZ = 0x7E01BFF;
    (DBGMCU)->APB2FZ = 0x70003;
  /* USER CODE END 1 */

  /* MCU Configuration--------------------------------------------------------*/

  /* Reset of all peripherals, Initializes the Flash interface and the Systick. */
  HAL_Init();

  /* Configure the system clock */
  SystemClock_Config();

  /* Initialize all configured peripherals */
  MX_GPIO_Init();
  MX_DMA_Init();
  MX_ADC3_Init();
  MX_CRC_Init();
  MX_DMA2D_Init();
  MX_I2C1_Init();
  MX_I2C3_Init();
  MX_LTDC_Init();
  MX_QUADSPI_Init();
  MX_RTC_Init();
  MX_TIM1_Init();
  MX_TIM2_Init();
  MX_TIM3_Init();
  MX_TIM5_Init();
  MX_TIM8_Init();
  MX_USART1_UART_Init();
  /* USER CODE BEGIN 2 */
  demo_init();
  /* USER CODE END 2 */

  /* Infinite loop */
  /* USER CODE BEGIN WHILE */

  while (1)
  {
	  demo_loop();
  }
    /* USER CODE END WHILE */

}

void SystemClock_Config(void)
{
  RCC_OscInitTypeDef RCC_OscInitStruct = {0};
  RCC_ClkInitTypeDef RCC_ClkInitStruct = {0};
  RCC_PeriphCLKInitTypeDef PeriphClkInitStruct = {0};

  /** Configure LSE Drive Capability
  */
  HAL_PWR_EnableBkUpAccess();
  /** Configure the main internal regulator output voltage
  */
  __HAL_RCC_PWR_CLK_ENABLE();
  __HAL_PWR_VOLTAGESCALING_CONFIG(PWR_REGULATOR_VOLTAGE_SCALE1);
  /** Initializes the CPU, AHB and APB busses clocks
  */
  RCC_OscInitStruct.OscillatorType = RCC_OSCILLATORTYPE_LSI|RCC_OSCILLATORTYPE_HSE;
  RCC_OscInitStruct.HSEState = RCC_HSE_ON;
  RCC_OscInitStruct.LSIState = RCC_LSI_ON;
  RCC_OscInitStruct.PLL.PLLState = RCC_PLL_ON;
  RCC_OscInitStruct.PLL.PLLSource = RCC_PLLSOURCE_HSE;
  RCC_OscInitStruct.PLL.PLLM = 25;
  RCC_OscInitStruct.PLL.PLLN = 400;
  RCC_OscInitStruct.PLL.PLLP = RCC_PLLP_DIV2;
  RCC_OscInitStruct.PLL.PLLQ = 9;
  if (HAL_RCC_OscConfig(&RCC_OscInitStruct) != HAL_OK)
  {
    Error_Handler();
  }
  /** Activate the Over-Drive mode
  */
  if (HAL_PWREx_EnableOverDrive() != HAL_OK)
  {
    Error_Handler();
  }
  /** Initializes the CPU, AHB and APB busses clocks
  */
  RCC_ClkInitStruct.ClockType = RCC_CLOCKTYPE_HCLK|RCC_CLOCKTYPE_SYSCLK
                              |RCC_CLOCKTYPE_PCLK1|RCC_CLOCKTYPE_PCLK2;
  RCC_ClkInitStruct.SYSCLKSource = RCC_SYSCLKSOURCE_PLLCLK;
  RCC_ClkInitStruct.AHBCLKDivider = RCC_SYSCLK_DIV1;
  RCC_ClkInitStruct.APB1CLKDivider = RCC_HCLK_DIV4;
  RCC_ClkInitStruct.APB2CLKDivider = RCC_HCLK_DIV2;

  if (HAL_RCC_ClockConfig(&RCC_ClkInitStruct, FLASH_LATENCY_6) != HAL_OK)
  {
    Error_Handler();
  }
  PeriphClkInitStruct.PeriphClockSelection = RCC_PERIPHCLK_LTDC|RCC_PERIPHCLK_RTC
                              |RCC_PERIPHCLK_USART1|RCC_PERIPHCLK_I2C1
                              |RCC_PERIPHCLK_I2C3;
  PeriphClkInitStruct.PLLSAI.PLLSAIN = 384;
  PeriphClkInitStruct.PLLSAI.PLLSAIR = 5;
  PeriphClkInitStruct.PLLSAI.PLLSAIQ = 2;
  PeriphClkInitStruct.PLLSAI.PLLSAIP = RCC_PLLSAIP_DIV8;
  PeriphClkInitStruct.PLLSAIDivQ = 1;
  PeriphClkInitStruct.PLLSAIDivR = RCC_PLLSAIDIVR_8;
  PeriphClkInitStruct.RTCClockSelection = RCC_RTCCLKSOURCE_LSI;
  PeriphClkInitStruct.Usart1ClockSelection = RCC_USART1CLKSOURCE_PCLK2;
  PeriphClkInitStruct.I2c1ClockSelection = RCC_I2C1CLKSOURCE_PCLK1;
  PeriphClkInitStruct.I2c3ClockSelection = RCC_I2C3CLKSOURCE_PCLK1;
  if (HAL_RCCEx_PeriphCLKConfig(&PeriphClkInitStruct) != HAL_OK)
  {
    Error_Handler();
  }
}

static void MX_ADC3_Init(void)
{

  ADC_ChannelConfTypeDef sConfig = {0};

  /** Configure the global features of the ADC (Clock, Resolution, Data Alignment and number of conversion)
  */
  hadc3.Instance = ADC3;
  hadc3.Init.ClockPrescaler = ADC_CLOCK_SYNC_PCLK_DIV4;
  hadc3.Init.Resolution = ADC_RESOLUTION_12B;
  hadc3.Init.ScanConvMode = ADC_SCAN_ENABLE;
  hadc3.Init.ContinuousConvMode = ENABLE;
  hadc3.Init.DiscontinuousConvMode = DISABLE;
  hadc3.Init.ExternalTrigConvEdge = ADC_EXTERNALTRIGCONVEDGE_NONE;
  hadc3.Init.ExternalTrigConv = ADC_SOFTWARE_START;
  hadc3.Init.DataAlign = ADC_DATAALIGN_RIGHT;
  hadc3.Init.NbrOfConversion = 5;
  hadc3.Init.DMAContinuousRequests = ENABLE;
  hadc3.Init.EOCSelection = ADC_EOC_SEQ_CONV;
  if (HAL_ADC_Init(&hadc3) != HAL_OK)
  {
    Error_Handler();
  }
  /** Configure for the selected ADC regular channel its corresponding rank in the sequencer and its sample time.
  */
  sConfig.Channel = ADC_CHANNEL_0;
  sConfig.Rank = ADC_REGULAR_RANK_1;
  sConfig.SamplingTime = ADC_SAMPLETIME_56CYCLES;
  if (HAL_ADC_ConfigChannel(&hadc3, &sConfig) != HAL_OK)
  {
    Error_Handler();
  }
  /** Configure for the selected ADC regular channel its corresponding rank in the sequencer and its sample time.
  */
  sConfig.Channel = ADC_CHANNEL_8;
  sConfig.Rank = ADC_REGULAR_RANK_2;
  if (HAL_ADC_ConfigChannel(&hadc3, &sConfig) != HAL_OK)
  {
    Error_Handler();
  }
  /** Configure for the selected ADC regular channel its corresponding rank in the sequencer and its sample time.
  */
  sConfig.Channel = ADC_CHANNEL_7;
  sConfig.Rank = ADC_REGULAR_RANK_3;
  if (HAL_ADC_ConfigChannel(&hadc3, &sConfig) != HAL_OK)
  {
    Error_Handler();
  }
  /** Configure for the selected ADC regular channel its corresponding rank in the sequencer and its sample time.
  */
  sConfig.Channel = ADC_CHANNEL_6;
  sConfig.Rank = ADC_REGULAR_RANK_4;
  if (HAL_ADC_ConfigChannel(&hadc3, &sConfig) != HAL_OK)
  {
    Error_Handler();
  }
  /** Configure for the selected ADC regular channel its corresponding rank in the sequencer and its sample time.
  */
  sConfig.Channel = ADC_CHANNEL_5;
  sConfig.Rank = ADC_REGULAR_RANK_5;
  if (HAL_ADC_ConfigChannel(&hadc3, &sConfig) != HAL_OK)
  {
    Error_Handler();
  }

}

static void MX_CRC_Init(void)
{

  hcrc.Instance = CRC;
  hcrc.Init.DefaultPolynomialUse = DEFAULT_POLYNOMIAL_ENABLE;
  hcrc.Init.DefaultInitValueUse = DEFAULT_INIT_VALUE_ENABLE;
  hcrc.Init.InputDataInversionMode = CRC_INPUTDATA_INVERSION_NONE;
  hcrc.Init.OutputDataInversionMode = CRC_OUTPUTDATA_INVERSION_DISABLE;
  hcrc.InputDataFormat = CRC_INPUTDATA_FORMAT_BYTES;
  if (HAL_CRC_Init(&hcrc) != HAL_OK)
  {
    Error_Handler();
  }

}

static void MX_DMA2D_Init(void)
{

  hdma2d.Instance = DMA2D;
  hdma2d.Init.Mode = DMA2D_M2M;
  hdma2d.Init.ColorMode = DMA2D_OUTPUT_ARGB8888;
  hdma2d.Init.OutputOffset = 0;
  hdma2d.LayerCfg[1].InputOffset = 0;
  hdma2d.LayerCfg[1].InputColorMode = DMA2D_INPUT_ARGB8888;
  hdma2d.LayerCfg[1].AlphaMode = DMA2D_NO_MODIF_ALPHA;
  hdma2d.LayerCfg[1].InputAlpha = 0;
  if (HAL_DMA2D_Init(&hdma2d) != HAL_OK)
  {
    Error_Handler();
  }
  if (HAL_DMA2D_ConfigLayer(&hdma2d, 1) != HAL_OK)
  {
    Error_Handler();
  }

}

static void MX_I2C1_Init(void)
{

  hi2c1.Instance = I2C1;
  hi2c1.Init.Timing = 0x00C0EAFF;
  hi2c1.Init.OwnAddress1 = 0;
  hi2c1.Init.AddressingMode = I2C_ADDRESSINGMODE_7BIT;
  hi2c1.Init.DualAddressMode = I2C_DUALADDRESS_DISABLE;
  hi2c1.Init.OwnAddress2 = 0;
  hi2c1.Init.OwnAddress2Masks = I2C_OA2_NOMASK;
  hi2c1.Init.GeneralCallMode = I2C_GENERALCALL_DISABLE;
  hi2c1.Init.NoStretchMode = I2C_NOSTRETCH_DISABLE;
  if (HAL_I2C_Init(&hi2c1) != HAL_OK)
  {
    Error_Handler();
  }
  /** Configure Analogue filter
  */
  if (HAL_I2CEx_ConfigAnalogFilter(&hi2c1, I2C_ANALOGFILTER_ENABLE) != HAL_OK)
  {
    Error_Handler();
  }
  /** Configure Digital filter
  */
  if (HAL_I2CEx_ConfigDigitalFilter(&hi2c1, 0) != HAL_OK)
  {
    Error_Handler();
  }

}

static void MX_I2C3_Init(void)
{

  hi2c3.Instance = I2C3;
  hi2c3.Init.Timing = 0x00401959;
  hi2c3.Init.OwnAddress1 = 0;
  hi2c3.Init.AddressingMode = I2C_ADDRESSINGMODE_7BIT;
  hi2c3.Init.DualAddressMode = I2C_DUALADDRESS_DISABLE;
  hi2c3.Init.OwnAddress2 = 0;
  hi2c3.Init.OwnAddress2Masks = I2C_OA2_NOMASK;
  hi2c3.Init.GeneralCallMode = I2C_GENERALCALL_DISABLE;
  hi2c3.Init.NoStretchMode = I2C_NOSTRETCH_DISABLE;
  if (HAL_I2C_Init(&hi2c3) != HAL_OK)
  {
    Error_Handler();
  }
  /** Configure Analogue filter
  */
  if (HAL_I2CEx_ConfigAnalogFilter(&hi2c3, I2C_ANALOGFILTER_ENABLE) != HAL_OK)
  {
    Error_Handler();
  }
  /** Configure Digital filter
  */
  if (HAL_I2CEx_ConfigDigitalFilter(&hi2c3, 0) != HAL_OK)
  {
    Error_Handler();
  }

}

static void MX_LTDC_Init(void)
{

  LTDC_LayerCfgTypeDef pLayerCfg = {0};

  hltdc.Instance = LTDC;
  hltdc.Init.HSPolarity = LTDC_HSPOLARITY_AL;
  hltdc.Init.VSPolarity = LTDC_VSPOLARITY_AL;
  hltdc.Init.DEPolarity = LTDC_DEPOLARITY_AL;
  hltdc.Init.PCPolarity = LTDC_PCPOLARITY_IPC;
  hltdc.Init.HorizontalSync = 40;
  hltdc.Init.VerticalSync = 9;
  hltdc.Init.AccumulatedHBP = 53;
  hltdc.Init.AccumulatedVBP = 11;
  hltdc.Init.AccumulatedActiveW = 533;
  hltdc.Init.AccumulatedActiveH = 283;
  hltdc.Init.TotalWidth = 565;
  hltdc.Init.TotalHeigh = 285;
  hltdc.Init.Backcolor.Blue = 0;
  hltdc.Init.Backcolor.Green = 0;
  hltdc.Init.Backcolor.Red = 0;
  if (HAL_LTDC_Init(&hltdc) != HAL_OK)
  {
    Error_Handler();
  }
  pLayerCfg.WindowX0 = 0;
  pLayerCfg.WindowX1 = 480;
  pLayerCfg.WindowY0 = 0;
  pLayerCfg.WindowY1 = 272;
  pLayerCfg.PixelFormat = LTDC_PIXEL_FORMAT_RGB565;
  pLayerCfg.Alpha = 255;
  pLayerCfg.Alpha0 = 0;
  pLayerCfg.BlendingFactor1 = LTDC_BLENDING_FACTOR1_PAxCA;
  pLayerCfg.BlendingFactor2 = LTDC_BLENDING_FACTOR2_PAxCA;
  pLayerCfg.FBStartAdress = 0xC0000000;
  pLayerCfg.ImageWidth = 480;
  pLayerCfg.ImageHeight = 272;
  pLayerCfg.Backcolor.Blue = 0;
  pLayerCfg.Backcolor.Green = 0;
  pLayerCfg.Backcolor.Red = 0;
  if (HAL_LTDC_ConfigLayer(&hltdc, &pLayerCfg, 0) != HAL_OK)
  {
    Error_Handler();
  }

}

static void MX_QUADSPI_Init(void)
{

  /* QUADSPI parameter configuration*/
  hqspi.Instance = QUADSPI;
  hqspi.Init.ClockPrescaler = 255;
  hqspi.Init.FifoThreshold = 1;
  hqspi.Init.SampleShifting = QSPI_SAMPLE_SHIFTING_NONE;
  hqspi.Init.FlashSize = 1;
  hqspi.Init.ChipSelectHighTime = QSPI_CS_HIGH_TIME_1_CYCLE;
  hqspi.Init.ClockMode = QSPI_CLOCK_MODE_0;
  hqspi.Init.FlashID = QSPI_FLASH_ID_1;
  hqspi.Init.DualFlash = QSPI_DUALFLASH_DISABLE;
  if (HAL_QSPI_Init(&hqspi) != HAL_OK)
  {
    Error_Handler();
  }

}

static void MX_RTC_Init(void)
{

  RTC_TimeTypeDef sTime = {0};
  RTC_DateTypeDef sDate = {0};
  RTC_AlarmTypeDef sAlarm = {0};

  /** Initialize RTC Only
  */
  hrtc.Instance = RTC;
  hrtc.Init.HourFormat = RTC_HOURFORMAT_24;
  hrtc.Init.AsynchPrediv = 127;
  hrtc.Init.SynchPrediv = 255;
  hrtc.Init.OutPut = RTC_OUTPUT_DISABLE;
  hrtc.Init.OutPutPolarity = RTC_OUTPUT_POLARITY_HIGH;
  hrtc.Init.OutPutType = RTC_OUTPUT_TYPE_OPENDRAIN;
  if (HAL_RTC_Init(&hrtc) != HAL_OK)
  {
    Error_Handler();
  }

  /** Initialize RTC and set the Time and Date
  */
  sTime.Hours = 0x0;
  sTime.Minutes = 0x0;
  sTime.Seconds = 0x0;
  sTime.DayLightSaving = RTC_DAYLIGHTSAVING_NONE;
  sTime.StoreOperation = RTC_STOREOPERATION_RESET;
  if (HAL_RTC_SetTime(&hrtc, &sTime, RTC_FORMAT_BCD) != HAL_OK)
  {
    Error_Handler();
  }
  sDate.WeekDay = RTC_WEEKDAY_MONDAY;
  sDate.Month = RTC_MONTH_JANUARY;
  sDate.Date = 0x1;
  sDate.Year = 0x0;
  if (HAL_RTC_SetDate(&hrtc, &sDate, RTC_FORMAT_BCD) != HAL_OK)
  {
    Error_Handler();
  }
  /** Enable the Alarm A
  */
  sAlarm.AlarmTime.Hours = 0x0;
  sAlarm.AlarmTime.Minutes = 0x0;
  sAlarm.AlarmTime.Seconds = 0x0;
  sAlarm.AlarmTime.SubSeconds = 0x0;
  sAlarm.AlarmTime.DayLightSaving = RTC_DAYLIGHTSAVING_NONE;
  sAlarm.AlarmTime.StoreOperation = RTC_STOREOPERATION_RESET;
  sAlarm.AlarmMask = RTC_ALARMMASK_NONE;
  sAlarm.AlarmSubSecondMask = RTC_ALARMSUBSECONDMASK_ALL;
  sAlarm.AlarmDateWeekDaySel = RTC_ALARMDATEWEEKDAYSEL_DATE;
  sAlarm.AlarmDateWeekDay = 0x1;
  sAlarm.Alarm = RTC_ALARM_A;
  if (HAL_RTC_SetAlarm(&hrtc, &sAlarm, RTC_FORMAT_BCD) != HAL_OK)
  {
    Error_Handler();
  }
  /** Enable the Alarm B
  */
  sAlarm.AlarmDateWeekDay = 0x1;
  sAlarm.Alarm = RTC_ALARM_B;
  if (HAL_RTC_SetAlarm(&hrtc, &sAlarm, RTC_FORMAT_BCD) != HAL_OK)
  {
    Error_Handler();
  }
  /** Enable the TimeStamp
  */
  if (HAL_RTCEx_SetTimeStamp(&hrtc, RTC_TIMESTAMPEDGE_RISING, RTC_TIMESTAMPPIN_POS1) != HAL_OK)
  {
    Error_Handler();
  }

}

static void MX_TIM1_Init(void)
{

  TIM_ClockConfigTypeDef sClockSourceConfig = {0};
  TIM_MasterConfigTypeDef sMasterConfig = {0};
  TIM_OC_InitTypeDef sConfigOC = {0};
  TIM_BreakDeadTimeConfigTypeDef sBreakDeadTimeConfig = {0};

  htim1.Instance = TIM1;
  htim1.Init.Prescaler = 0;
  htim1.Init.CounterMode = TIM_COUNTERMODE_UP;
  htim1.Init.Period = 2000;
  htim1.Init.ClockDivision = TIM_CLOCKDIVISION_DIV1;
  htim1.Init.RepetitionCounter = 0;
  htim1.Init.AutoReloadPreload = TIM_AUTORELOAD_PRELOAD_ENABLE;
  if (HAL_TIM_Base_Init(&htim1) != HAL_OK)
  {
    Error_Handler();
  }
  sClockSourceConfig.ClockSource = TIM_CLOCKSOURCE_INTERNAL;
  if (HAL_TIM_ConfigClockSource(&htim1, &sClockSourceConfig) != HAL_OK)
  {
    Error_Handler();
  }
  if (HAL_TIM_PWM_Init(&htim1) != HAL_OK)
  {
    Error_Handler();
  }
  sMasterConfig.MasterOutputTrigger = TIM_TRGO_RESET;
  sMasterConfig.MasterOutputTrigger2 = TIM_TRGO2_RESET;
  sMasterConfig.MasterSlaveMode = TIM_MASTERSLAVEMODE_DISABLE;
  if (HAL_TIMEx_MasterConfigSynchronization(&htim1, &sMasterConfig) != HAL_OK)
  {
    Error_Handler();
  }
  sConfigOC.OCMode = TIM_OCMODE_PWM1;
  sConfigOC.Pulse = 0;
  sConfigOC.OCPolarity = TIM_OCPOLARITY_HIGH;
  sConfigOC.OCNPolarity = TIM_OCNPOLARITY_HIGH;
  sConfigOC.OCFastMode = TIM_OCFAST_DISABLE;
  sConfigOC.OCIdleState = TIM_OCIDLESTATE_RESET;
  sConfigOC.OCNIdleState = TIM_OCNIDLESTATE_RESET;
  if (HAL_TIM_PWM_ConfigChannel(&htim1, &sConfigOC, TIM_CHANNEL_1) != HAL_OK)
  {
    Error_Handler();
  }
  sBreakDeadTimeConfig.OffStateRunMode = TIM_OSSR_DISABLE;
  sBreakDeadTimeConfig.OffStateIDLEMode = TIM_OSSI_DISABLE;
  sBreakDeadTimeConfig.LockLevel = TIM_LOCKLEVEL_OFF;
  sBreakDeadTimeConfig.DeadTime = 0;
  sBreakDeadTimeConfig.BreakState = TIM_BREAK_DISABLE;
  sBreakDeadTimeConfig.BreakPolarity = TIM_BREAKPOLARITY_HIGH;
  sBreakDeadTimeConfig.BreakFilter = 0;
  sBreakDeadTimeConfig.Break2State = TIM_BREAK2_DISABLE;
  sBreakDeadTimeConfig.Break2Polarity = TIM_BREAK2POLARITY_HIGH;
  sBreakDeadTimeConfig.Break2Filter = 0;
  sBreakDeadTimeConfig.AutomaticOutput = TIM_AUTOMATICOUTPUT_DISABLE;
  if (HAL_TIMEx_ConfigBreakDeadTime(&htim1, &sBreakDeadTimeConfig) != HAL_OK)
  {
    Error_Handler();
  }
  HAL_TIM_MspPostInit(&htim1);

}

static void MX_TIM2_Init(void)
{

  TIM_ClockConfigTypeDef sClockSourceConfig = {0};
  TIM_MasterConfigTypeDef sMasterConfig = {0};

  htim2.Instance = TIM2;
  htim2.Init.Prescaler = 0;
  htim2.Init.CounterMode = TIM_COUNTERMODE_UP;
  htim2.Init.Period = 0;
  htim2.Init.ClockDivision = TIM_CLOCKDIVISION_DIV1;
  htim2.Init.AutoReloadPreload = TIM_AUTORELOAD_PRELOAD_DISABLE;
  if (HAL_TIM_Base_Init(&htim2) != HAL_OK)
  {
    Error_Handler();
  }
  sClockSourceConfig.ClockSource = TIM_CLOCKSOURCE_INTERNAL;
  if (HAL_TIM_ConfigClockSource(&htim2, &sClockSourceConfig) != HAL_OK)
  {
    Error_Handler();
  }
  sMasterConfig.MasterOutputTrigger = TIM_TRGO_RESET;
  sMasterConfig.MasterSlaveMode = TIM_MASTERSLAVEMODE_DISABLE;
  if (HAL_TIMEx_MasterConfigSynchronization(&htim2, &sMasterConfig) != HAL_OK)
  {
    Error_Handler();
  }

}

static void MX_TIM3_Init(void)
{

  TIM_ClockConfigTypeDef sClockSourceConfig = {0};
  TIM_MasterConfigTypeDef sMasterConfig = {0};

  htim3.Instance = TIM3;
  htim3.Init.Prescaler = 0;
  htim3.Init.CounterMode = TIM_COUNTERMODE_UP;
  htim3.Init.Period = 0;
  htim3.Init.ClockDivision = TIM_CLOCKDIVISION_DIV1;
  htim3.Init.AutoReloadPreload = TIM_AUTORELOAD_PRELOAD_DISABLE;
  if (HAL_TIM_Base_Init(&htim3) != HAL_OK)
  {
    Error_Handler();
  }
  sClockSourceConfig.ClockSource = TIM_CLOCKSOURCE_INTERNAL;
  if (HAL_TIM_ConfigClockSource(&htim3, &sClockSourceConfig) != HAL_OK)
  {
    Error_Handler();
  }
  sMasterConfig.MasterOutputTrigger = TIM_TRGO_RESET;
  sMasterConfig.MasterSlaveMode = TIM_MASTERSLAVEMODE_DISABLE;
  if (HAL_TIMEx_MasterConfigSynchronization(&htim3, &sMasterConfig) != HAL_OK)
  {
    Error_Handler();
  }

}

static void MX_TIM5_Init(void)
{

  TIM_ClockConfigTypeDef sClockSourceConfig = {0};
  TIM_MasterConfigTypeDef sMasterConfig = {0};

  htim5.Instance = TIM5;
  htim5.Init.Prescaler = 0;
  htim5.Init.CounterMode = TIM_COUNTERMODE_UP;
  htim5.Init.Period = 0;
  htim5.Init.ClockDivision = TIM_CLOCKDIVISION_DIV1;
  htim5.Init.AutoReloadPreload = TIM_AUTORELOAD_PRELOAD_DISABLE;
  if (HAL_TIM_Base_Init(&htim5) != HAL_OK)
  {
    Error_Handler();
  }
  sClockSourceConfig.ClockSource = TIM_CLOCKSOURCE_INTERNAL;
  if (HAL_TIM_ConfigClockSource(&htim5, &sClockSourceConfig) != HAL_OK)
  {
    Error_Handler();
  }
  sMasterConfig.MasterOutputTrigger = TIM_TRGO_RESET;
  sMasterConfig.MasterSlaveMode = TIM_MASTERSLAVEMODE_DISABLE;
  if (HAL_TIMEx_MasterConfigSynchronization(&htim5, &sMasterConfig) != HAL_OK)
  {
    Error_Handler();
  }

}

static void MX_TIM8_Init(void)
{

  TIM_ClockConfigTypeDef sClockSourceConfig = {0};
  TIM_MasterConfigTypeDef sMasterConfig = {0};
  TIM_OC_InitTypeDef sConfigOC = {0};
  TIM_BreakDeadTimeConfigTypeDef sBreakDeadTimeConfig = {0};

  htim8.Instance = TIM8;
  htim8.Init.Prescaler = 0;
  htim8.Init.CounterMode = TIM_COUNTERMODE_UP;
  htim8.Init.Period = 4000;
  htim8.Init.ClockDivision = TIM_CLOCKDIVISION_DIV1;
  htim8.Init.RepetitionCounter = 0;
  htim8.Init.AutoReloadPreload = TIM_AUTORELOAD_PRELOAD_ENABLE;
  if (HAL_TIM_Base_Init(&htim8) != HAL_OK)
  {
    Error_Handler();
  }
  sClockSourceConfig.ClockSource = TIM_CLOCKSOURCE_INTERNAL;
  if (HAL_TIM_ConfigClockSource(&htim8, &sClockSourceConfig) != HAL_OK)
  {
    Error_Handler();
  }
  if (HAL_TIM_PWM_Init(&htim8) != HAL_OK)
  {
    Error_Handler();
  }
  sMasterConfig.MasterOutputTrigger = TIM_TRGO_RESET;
  sMasterConfig.MasterOutputTrigger2 = TIM_TRGO2_RESET;
  sMasterConfig.MasterSlaveMode = TIM_MASTERSLAVEMODE_DISABLE;
  if (HAL_TIMEx_MasterConfigSynchronization(&htim8, &sMasterConfig) != HAL_OK)
  {
    Error_Handler();
  }
  sConfigOC.OCMode = TIM_OCMODE_COMBINED_PWM1;
  sConfigOC.Pulse = 0;
  sConfigOC.OCPolarity = TIM_OCPOLARITY_HIGH;
  sConfigOC.OCNPolarity = TIM_OCNPOLARITY_HIGH;
  sConfigOC.OCFastMode = TIM_OCFAST_DISABLE;
  sConfigOC.OCIdleState = TIM_OCIDLESTATE_RESET;
  sConfigOC.OCNIdleState = TIM_OCNIDLESTATE_RESET;
  if (HAL_TIM_PWM_ConfigChannel(&htim8, &sConfigOC, TIM_CHANNEL_2) != HAL_OK)
  {
    Error_Handler();
  }
  __HAL_TIM_DISABLE_OCxPRELOAD(&htim8, TIM_CHANNEL_2);
  sBreakDeadTimeConfig.OffStateRunMode = TIM_OSSR_DISABLE;
  sBreakDeadTimeConfig.OffStateIDLEMode = TIM_OSSI_DISABLE;
  sBreakDeadTimeConfig.LockLevel = TIM_LOCKLEVEL_OFF;
  sBreakDeadTimeConfig.DeadTime = 10;
  sBreakDeadTimeConfig.BreakState = TIM_BREAK_DISABLE;
  sBreakDeadTimeConfig.BreakPolarity = TIM_BREAKPOLARITY_HIGH;
  sBreakDeadTimeConfig.BreakFilter = 0;
  sBreakDeadTimeConfig.Break2State = TIM_BREAK2_DISABLE;
  sBreakDeadTimeConfig.Break2Polarity = TIM_BREAK2POLARITY_HIGH;
  sBreakDeadTimeConfig.Break2Filter = 0;
  sBreakDeadTimeConfig.AutomaticOutput = TIM_AUTOMATICOUTPUT_DISABLE;
  if (HAL_TIMEx_ConfigBreakDeadTime(&htim8, &sBreakDeadTimeConfig) != HAL_OK)
  {
    Error_Handler();
  }
  HAL_TIM_MspPostInit(&htim8);

}

static void MX_USART1_UART_Init(void)
{

  huart1.Instance = USART1;
  huart1.Init.BaudRate = 115200;
  huart1.Init.WordLength = UART_WORDLENGTH_8B;
  huart1.Init.StopBits = UART_STOPBITS_1;
  huart1.Init.Parity = UART_PARITY_NONE;
  huart1.Init.Mode = UART_MODE_TX_RX;
  huart1.Init.HwFlowCtl = UART_HWCONTROL_NONE;
  huart1.Init.OverSampling = UART_OVERSAMPLING_16;
  huart1.Init.OneBitSampling = UART_ONE_BIT_SAMPLE_DISABLE;
  huart1.AdvancedInit.AdvFeatureInit = UART_ADVFEATURE_NO_INIT;
  if (HAL_UART_Init(&huart1) != HAL_OK)
  {
    Error_Handler();
  }

}

static void MX_DMA_Init(void)
{

  /* DMA controller clock enable */
  __HAL_RCC_DMA2_CLK_ENABLE();

  /* DMA interrupt init */
  /* DMA2_Stream0_IRQn interrupt configuration */
  HAL_NVIC_SetPriority(DMA2_Stream0_IRQn, 0, 0);
  HAL_NVIC_EnableIRQ(DMA2_Stream0_IRQn);

}

static void MX_GPIO_Init(void)
{
  GPIO_InitTypeDef GPIO_InitStruct = {0};

  /* GPIO Ports Clock Enable */
  __HAL_RCC_GPIOE_CLK_ENABLE();
  __HAL_RCC_GPIOG_CLK_ENABLE();
  __HAL_RCC_GPIOB_CLK_ENABLE();
  __HAL_RCC_GPIOD_CLK_ENABLE();
  __HAL_RCC_GPIOC_CLK_ENABLE();
  __HAL_RCC_GPIOA_CLK_ENABLE();
  __HAL_RCC_GPIOJ_CLK_ENABLE();
  __HAL_RCC_GPIOI_CLK_ENABLE();
  __HAL_RCC_GPIOK_CLK_ENABLE();
  __HAL_RCC_GPIOF_CLK_ENABLE();
  __HAL_RCC_GPIOH_CLK_ENABLE();

  /*Configure GPIO pin Output Level */
  HAL_GPIO_WritePin(OTG_FS_PowerSwitchOn_GPIO_Port, OTG_FS_PowerSwitchOn_Pin, GPIO_PIN_SET);

  /*Configure GPIO pin Output Level */
  HAL_GPIO_WritePin(LCD_BL_CTRL_GPIO_Port, LCD_BL_CTRL_Pin, GPIO_PIN_SET);

  /*Configure GPIO pin Output Level */
  HAL_GPIO_WritePin(LCD_DISP_GPIO_Port, LCD_DISP_Pin, GPIO_PIN_SET);

  /*Configure GPIO pin Output Level */
  HAL_GPIO_WritePin(GPIOC, GPIO_PIN_6, GPIO_PIN_RESET);

  /*Configure GPIO pin Output Level */
  HAL_GPIO_WritePin(EXT_RST_GPIO_Port, EXT_RST_Pin, GPIO_PIN_RESET);

  /*Configure GPIO pin Output Level */
  HAL_GPIO_WritePin(EBUZZ_M_GPIO_Port, EBUZZ_M_Pin, GPIO_PIN_RESET);

  /*Configure GPIO pin Output Level */
  HAL_GPIO_WritePin(EBUZZ_P_GPIO_Port, EBUZZ_P_Pin, GPIO_PIN_RESET);

  /*Configure GPIO pin : OTG_HS_OverCurrent_Pin */
  GPIO_InitStruct.Pin = OTG_HS_OverCurrent_Pin;
  GPIO_InitStruct.Mode = GPIO_MODE_INPUT;
  GPIO_InitStruct.Pull = GPIO_NOPULL;
  HAL_GPIO_Init(OTG_HS_OverCurrent_GPIO_Port, &GPIO_InitStruct);

  /*Configure GPIO pins : RMII_TXD1_Pin RMII_TXD0_Pin RMII_TX_EN_Pin */
  GPIO_InitStruct.Pin = RMII_TXD1_Pin|RMII_TXD0_Pin|RMII_TX_EN_Pin;
  GPIO_InitStruct.Mode = GPIO_MODE_AF_PP;
  GPIO_InitStruct.Pull = GPIO_NOPULL;
  GPIO_InitStruct.Speed = GPIO_SPEED_FREQ_VERY_HIGH;
  GPIO_InitStruct.Alternate = GPIO_AF11_ETH;
  HAL_GPIO_Init(GPIOG, &GPIO_InitStruct);

  /*Configure GPIO pins : FMC_NBL1_Pin FMC_NBL0_Pin FMC_D5_Pin FMC_D6_Pin
                           FMC_D8_Pin FMC_D11_Pin FMC_D4_Pin FMC_D7_Pin
                           FMC_D9_Pin FMC_D12_Pin FMC_D10_Pin */
  GPIO_InitStruct.Pin = FMC_NBL1_Pin|FMC_NBL0_Pin|FMC_D5_Pin|FMC_D6_Pin
                          |FMC_D8_Pin|FMC_D11_Pin|FMC_D4_Pin|FMC_D7_Pin
                          |FMC_D9_Pin|FMC_D12_Pin|FMC_D10_Pin;
  GPIO_InitStruct.Mode = GPIO_MODE_AF_PP;
  GPIO_InitStruct.Pull = GPIO_NOPULL;
  GPIO_InitStruct.Speed = GPIO_SPEED_FREQ_VERY_HIGH;
  GPIO_InitStruct.Alternate = GPIO_AF12_FMC;
  HAL_GPIO_Init(GPIOE, &GPIO_InitStruct);

  /*Configure GPIO pins : ULPI_D7_Pin ULPI_D6_Pin ULPI_D5_Pin ULPI_D3_Pin
                           ULPI_D2_Pin ULPI_D1_Pin ULPI_D4_Pin */
  GPIO_InitStruct.Pin = ULPI_D7_Pin|ULPI_D6_Pin|ULPI_D5_Pin|ULPI_D3_Pin
                          |ULPI_D2_Pin|ULPI_D1_Pin|ULPI_D4_Pin;
  GPIO_InitStruct.Mode = GPIO_MODE_AF_PP;
  GPIO_InitStruct.Pull = GPIO_NOPULL;
  GPIO_InitStruct.Speed = GPIO_SPEED_FREQ_VERY_HIGH;
  GPIO_InitStruct.Alternate = GPIO_AF10_OTG_HS;
  HAL_GPIO_Init(GPIOB, &GPIO_InitStruct);

  /*Configure GPIO pin : PB4 */
  GPIO_InitStruct.Pin = GPIO_PIN_4;
  GPIO_InitStruct.Mode = GPIO_MODE_IT_RISING_FALLING;
  GPIO_InitStruct.Pull = GPIO_NOPULL;
  HAL_GPIO_Init(GPIOB, &GPIO_InitStruct);

  /*Configure GPIO pin : SPDIF_RX0_Pin */
  GPIO_InitStruct.Pin = SPDIF_RX0_Pin;
  GPIO_InitStruct.Mode = GPIO_MODE_AF_PP;
  GPIO_InitStruct.Pull = GPIO_NOPULL;
  GPIO_InitStruct.Speed = GPIO_SPEED_FREQ_LOW;
  GPIO_InitStruct.Alternate = GPIO_AF8_SPDIFRX;
  HAL_GPIO_Init(SPDIF_RX0_GPIO_Port, &GPIO_InitStruct);

  /*Configure GPIO pins : SDMMC_CK_Pin SDMMC_D3_Pin SDMMC_D2_Pin PC9
                           PC8 */
  GPIO_InitStruct.Pin = SDMMC_CK_Pin|SDMMC_D3_Pin|SDMMC_D2_Pin|GPIO_PIN_9
                          |GPIO_PIN_8;
  GPIO_InitStruct.Mode = GPIO_MODE_AF_PP;
  GPIO_InitStruct.Pull = GPIO_NOPULL;
  GPIO_InitStruct.Speed = GPIO_SPEED_FREQ_VERY_HIGH;
  GPIO_InitStruct.Alternate = GPIO_AF12_SDMMC1;
  HAL_GPIO_Init(GPIOC, &GPIO_InitStruct);

  /*Configure GPIO pin : PA15 */
  GPIO_InitStruct.Pin = GPIO_PIN_15;
  GPIO_InitStruct.Mode = GPIO_MODE_IT_RISING_FALLING;
  GPIO_InitStruct.Pull = GPIO_NOPULL;
  HAL_GPIO_Init(GPIOA, &GPIO_InitStruct);

  /*Configure GPIO pins : DCMI_D6_Pin DCMI_D7_Pin */
  GPIO_InitStruct.Pin = DCMI_D6_Pin|DCMI_D7_Pin;
  GPIO_InitStruct.Mode = GPIO_MODE_AF_PP;
  GPIO_InitStruct.Pull = GPIO_NOPULL;
  GPIO_InitStruct.Speed = GPIO_SPEED_FREQ_LOW;
  GPIO_InitStruct.Alternate = GPIO_AF13_DCMI;
  HAL_GPIO_Init(GPIOE, &GPIO_InitStruct);

  /*Configure GPIO pins : FMC_SDNCAS_Pin FMC_SDCLK_Pin FMC_A11_Pin FMC_A10_Pin
                           FMC_BA1_Pin FMC_BA0_Pin */
  GPIO_InitStruct.Pin = FMC_SDNCAS_Pin|FMC_SDCLK_Pin|FMC_A11_Pin|FMC_A10_Pin
                          |FMC_BA1_Pin|FMC_BA0_Pin;
  GPIO_InitStruct.Mode = GPIO_MODE_AF_PP;
  GPIO_InitStruct.Pull = GPIO_NOPULL;
  GPIO_InitStruct.Speed = GPIO_SPEED_FREQ_VERY_HIGH;
  GPIO_InitStruct.Alternate = GPIO_AF12_FMC;
  HAL_GPIO_Init(GPIOG, &GPIO_InitStruct);

  /*Configure GPIO pin : OTG_FS_VBUS_Pin */
  GPIO_InitStruct.Pin = OTG_FS_VBUS_Pin;
  GPIO_InitStruct.Mode = GPIO_MODE_INPUT;
  GPIO_InitStruct.Pull = GPIO_NOPULL;
  HAL_GPIO_Init(OTG_FS_VBUS_GPIO_Port, &GPIO_InitStruct);

  /*Configure GPIO pins : FMC_D2_Pin FMC_D3_Pin FMC_D1_Pin FMC_D15_Pin
                           FMC_D0_Pin FMC_D14_Pin FMC_D13_Pin */
  GPIO_InitStruct.Pin = FMC_D2_Pin|FMC_D3_Pin|FMC_D1_Pin|FMC_D15_Pin
                          |FMC_D0_Pin|FMC_D14_Pin|FMC_D13_Pin;
  GPIO_InitStruct.Mode = GPIO_MODE_AF_PP;
  GPIO_InitStruct.Pull = GPIO_NOPULL;
  GPIO_InitStruct.Speed = GPIO_SPEED_FREQ_VERY_HIGH;
  GPIO_InitStruct.Alternate = GPIO_AF12_FMC;
  HAL_GPIO_Init(GPIOD, &GPIO_InitStruct);

  /*Configure GPIO pins : OTG_FS_P_Pin OTG_FS_N_Pin OTG_FS_ID_Pin */
  GPIO_InitStruct.Pin = OTG_FS_P_Pin|OTG_FS_N_Pin|OTG_FS_ID_Pin;
  GPIO_InitStruct.Mode = GPIO_MODE_AF_PP;
  GPIO_InitStruct.Pull = GPIO_NOPULL;
  GPIO_InitStruct.Speed = GPIO_SPEED_FREQ_VERY_HIGH;
  GPIO_InitStruct.Alternate = GPIO_AF10_OTG_FS;
  HAL_GPIO_Init(GPIOA, &GPIO_InitStruct);

  /*Configure GPIO pins : SAI2_MCLKA_Pin SAI2_SCKA_Pin SAI2_FSA_Pin SAI2_SDA_Pin */
  GPIO_InitStruct.Pin = SAI2_MCLKA_Pin|SAI2_SCKA_Pin|SAI2_FSA_Pin|SAI2_SDA_Pin;
  GPIO_InitStruct.Mode = GPIO_MODE_AF_PP;
  GPIO_InitStruct.Pull = GPIO_NOPULL;
  GPIO_InitStruct.Speed = GPIO_SPEED_FREQ_LOW;
  GPIO_InitStruct.Alternate = GPIO_AF10_SAI2;
  HAL_GPIO_Init(GPIOI, &GPIO_InitStruct);

  /*Configure GPIO pin : SAI2_SDB_Pin */
  GPIO_InitStruct.Pin = SAI2_SDB_Pin;
  GPIO_InitStruct.Mode = GPIO_MODE_AF_PP;
  GPIO_InitStruct.Pull = GPIO_NOPULL;
  GPIO_InitStruct.Speed = GPIO_SPEED_FREQ_LOW;
  GPIO_InitStruct.Alternate = GPIO_AF10_SAI2;
  HAL_GPIO_Init(SAI2_SDB_GPIO_Port, &GPIO_InitStruct);

  /*Configure GPIO pin : OTG_FS_PowerSwitchOn_Pin */
  GPIO_InitStruct.Pin = OTG_FS_PowerSwitchOn_Pin;
  GPIO_InitStruct.Mode = GPIO_MODE_OUTPUT_PP;
  GPIO_InitStruct.Pull = GPIO_NOPULL;
  GPIO_InitStruct.Speed = GPIO_SPEED_FREQ_LOW;
  HAL_GPIO_Init(OTG_FS_PowerSwitchOn_GPIO_Port, &GPIO_InitStruct);

  /*Configure GPIO pin : DCMI_D5_Pin */
  GPIO_InitStruct.Pin = DCMI_D5_Pin;
  GPIO_InitStruct.Mode = GPIO_MODE_AF_PP;
  GPIO_InitStruct.Pull = GPIO_NOPULL;
  GPIO_InitStruct.Speed = GPIO_SPEED_FREQ_LOW;
  GPIO_InitStruct.Alternate = GPIO_AF13_DCMI;
  HAL_GPIO_Init(DCMI_D5_GPIO_Port, &GPIO_InitStruct);

  /*Configure GPIO pins : PI3 PI2 PI1 PI0
                           LCD_INT_Pin */
  GPIO_InitStruct.Pin = GPIO_PIN_3|GPIO_PIN_2|GPIO_PIN_1|GPIO_PIN_0
                          |LCD_INT_Pin;
  GPIO_InitStruct.Mode = GPIO_MODE_IT_RISING_FALLING;
  GPIO_InitStruct.Pull = GPIO_NOPULL;
  HAL_GPIO_Init(GPIOI, &GPIO_InitStruct);

  /*Configure GPIO pin : uSD_Detect_Pin */
  GPIO_InitStruct.Pin = uSD_Detect_Pin;
  GPIO_InitStruct.Mode = GPIO_MODE_INPUT;
  GPIO_InitStruct.Pull = GPIO_NOPULL;
  HAL_GPIO_Init(uSD_Detect_GPIO_Port, &GPIO_InitStruct);

  /*Configure GPIO pins : FMC_A0_Pin FMC_A1_Pin FMC_A2_Pin FMC_A3_Pin
                           FMC_A4_Pin FMC_A5_Pin FMC_A6_Pin FMC_A9_Pin
                           FMC_A7_Pin FMC_A8_Pin FMC_SDNRAS_Pin */
  GPIO_InitStruct.Pin = FMC_A0_Pin|FMC_A1_Pin|FMC_A2_Pin|FMC_A3_Pin
                          |FMC_A4_Pin|FMC_A5_Pin|FMC_A6_Pin|FMC_A9_Pin
                          |FMC_A7_Pin|FMC_A8_Pin|FMC_SDNRAS_Pin;
  GPIO_InitStruct.Mode = GPIO_MODE_AF_PP;
  GPIO_InitStruct.Pull = GPIO_NOPULL;
  GPIO_InitStruct.Speed = GPIO_SPEED_FREQ_VERY_HIGH;
  GPIO_InitStruct.Alternate = GPIO_AF12_FMC;
  HAL_GPIO_Init(GPIOF, &GPIO_InitStruct);

  /*Configure GPIO pin : LCD_BL_CTRL_Pin */
  GPIO_InitStruct.Pin = LCD_BL_CTRL_Pin;
  GPIO_InitStruct.Mode = GPIO_MODE_OUTPUT_PP;
  GPIO_InitStruct.Pull = GPIO_NOPULL;
  GPIO_InitStruct.Speed = GPIO_SPEED_FREQ_LOW;
  HAL_GPIO_Init(LCD_BL_CTRL_GPIO_Port, &GPIO_InitStruct);

  /*Configure GPIO pin : DCMI_VSYNC_Pin */
  GPIO_InitStruct.Pin = DCMI_VSYNC_Pin;
  GPIO_InitStruct.Mode = GPIO_MODE_AF_PP;
  GPIO_InitStruct.Pull = GPIO_NOPULL;
  GPIO_InitStruct.Speed = GPIO_SPEED_FREQ_LOW;
  GPIO_InitStruct.Alternate = GPIO_AF13_DCMI;
  HAL_GPIO_Init(DCMI_VSYNC_GPIO_Port, &GPIO_InitStruct);

  /*Configure GPIO pin : OTG_FS_OverCurrent_Pin */
  GPIO_InitStruct.Pin = OTG_FS_OverCurrent_Pin;
  GPIO_InitStruct.Mode = GPIO_MODE_INPUT;
  GPIO_InitStruct.Pull = GPIO_NOPULL;
  HAL_GPIO_Init(OTG_FS_OverCurrent_GPIO_Port, &GPIO_InitStruct);

  /*Configure GPIO pin : SDMMC_CMD_Pin */
  GPIO_InitStruct.Pin = SDMMC_CMD_Pin;
  GPIO_InitStruct.Mode = GPIO_MODE_AF_PP;
  GPIO_InitStruct.Pull = GPIO_NOPULL;
  GPIO_InitStruct.Speed = GPIO_SPEED_FREQ_VERY_HIGH;
  GPIO_InitStruct.Alternate = GPIO_AF12_SDMMC1;
  HAL_GPIO_Init(SDMMC_CMD_GPIO_Port, &GPIO_InitStruct);

  /*Configure GPIO pins : TP3_Pin NC2_Pin */
  GPIO_InitStruct.Pin = TP3_Pin|NC2_Pin;
  GPIO_InitStruct.Mode = GPIO_MODE_INPUT;
  GPIO_InitStruct.Pull = GPIO_NOPULL;
  HAL_GPIO_Init(GPIOH, &GPIO_InitStruct);

  /*Configure GPIO pin : LCD_DISP_Pin */
  GPIO_InitStruct.Pin = LCD_DISP_Pin;
  GPIO_InitStruct.Mode = GPIO_MODE_OUTPUT_PP;
  GPIO_InitStruct.Pull = GPIO_NOPULL;
  GPIO_InitStruct.Speed = GPIO_SPEED_FREQ_LOW;
  HAL_GPIO_Init(LCD_DISP_GPIO_Port, &GPIO_InitStruct);

  /*Configure GPIO pins : DCMI_D4_Pin DCMI_D3_Pin DCMI_D0_Pin DCMI_D2_Pin
                           DCMI_D1_Pin */
  GPIO_InitStruct.Pin = DCMI_D4_Pin|DCMI_D3_Pin|DCMI_D0_Pin|DCMI_D2_Pin
                          |DCMI_D1_Pin;
  GPIO_InitStruct.Mode = GPIO_MODE_AF_PP;
  GPIO_InitStruct.Pull = GPIO_NOPULL;
  GPIO_InitStruct.Speed = GPIO_SPEED_FREQ_LOW;
  GPIO_InitStruct.Alternate = GPIO_AF13_DCMI;
  HAL_GPIO_Init(GPIOH, &GPIO_InitStruct);

  /*Configure GPIO pin : ULPI_NXT_Pin */
  GPIO_InitStruct.Pin = ULPI_NXT_Pin;
  GPIO_InitStruct.Mode = GPIO_MODE_AF_PP;
  GPIO_InitStruct.Pull = GPIO_NOPULL;
  GPIO_InitStruct.Speed = GPIO_SPEED_FREQ_VERY_HIGH;
  GPIO_InitStruct.Alternate = GPIO_AF10_OTG_HS;
  HAL_GPIO_Init(ULPI_NXT_GPIO_Port, &GPIO_InitStruct);

  /*Configure GPIO pin : PC6 */
  GPIO_InitStruct.Pin = GPIO_PIN_6;
  GPIO_InitStruct.Mode = GPIO_MODE_OUTPUT_PP;
  GPIO_InitStruct.Pull = GPIO_NOPULL;
  GPIO_InitStruct.Speed = GPIO_SPEED_FREQ_LOW;
  HAL_GPIO_Init(GPIOC, &GPIO_InitStruct);

  /*Configure GPIO pins : FMC_SDNME_Pin FMC_SDNE0_Pin */
  GPIO_InitStruct.Pin = FMC_SDNME_Pin|FMC_SDNE0_Pin;
  GPIO_InitStruct.Mode = GPIO_MODE_AF_PP;
  GPIO_InitStruct.Pull = GPIO_NOPULL;
  GPIO_InitStruct.Speed = GPIO_SPEED_FREQ_VERY_HIGH;
  GPIO_InitStruct.Alternate = GPIO_AF12_FMC;
  HAL_GPIO_Init(GPIOH, &GPIO_InitStruct);

  /*Configure GPIO pins : PG7 PG6 */
  GPIO_InitStruct.Pin = GPIO_PIN_7|GPIO_PIN_6;
  GPIO_InitStruct.Mode = GPIO_MODE_IT_RISING_FALLING;
  GPIO_InitStruct.Pull = GPIO_NOPULL;
  HAL_GPIO_Init(GPIOG, &GPIO_InitStruct);

  /*Configure GPIO pin : FMC_SDCKE0_Pin */
  GPIO_InitStruct.Pin = FMC_SDCKE0_Pin;
  GPIO_InitStruct.Mode = GPIO_MODE_AF_PP;
  GPIO_InitStruct.Pull = GPIO_NOPULL;
  GPIO_InitStruct.Speed = GPIO_SPEED_FREQ_VERY_HIGH;
  GPIO_InitStruct.Alternate = GPIO_AF12_FMC;
  HAL_GPIO_Init(FMC_SDCKE0_GPIO_Port, &GPIO_InitStruct);

  /*Configure GPIO pins : ULPI_STP_Pin ULPI_DIR_Pin */
  GPIO_InitStruct.Pin = ULPI_STP_Pin|ULPI_DIR_Pin;
  GPIO_InitStruct.Mode = GPIO_MODE_AF_PP;
  GPIO_InitStruct.Pull = GPIO_NOPULL;
  GPIO_InitStruct.Speed = GPIO_SPEED_FREQ_VERY_HIGH;
  GPIO_InitStruct.Alternate = GPIO_AF10_OTG_HS;
  HAL_GPIO_Init(GPIOC, &GPIO_InitStruct);

  /*Configure GPIO pins : RMII_MDC_Pin RMII_RXD0_Pin RMII_RXD1_Pin */
  GPIO_InitStruct.Pin = RMII_MDC_Pin|RMII_RXD0_Pin|RMII_RXD1_Pin;
  GPIO_InitStruct.Mode = GPIO_MODE_AF_PP;
  GPIO_InitStruct.Pull = GPIO_NOPULL;
  GPIO_InitStruct.Speed = GPIO_SPEED_FREQ_VERY_HIGH;
  GPIO_InitStruct.Alternate = GPIO_AF11_ETH;
  HAL_GPIO_Init(GPIOC, &GPIO_InitStruct);

  /*Configure GPIO pin : EXT_RST_Pin */
  GPIO_InitStruct.Pin = EXT_RST_Pin;
  GPIO_InitStruct.Mode = GPIO_MODE_OUTPUT_PP;
  GPIO_InitStruct.Pull = GPIO_NOPULL;
  GPIO_InitStruct.Speed = GPIO_SPEED_FREQ_LOW;
  HAL_GPIO_Init(EXT_RST_GPIO_Port, &GPIO_InitStruct);

  /*Configure GPIO pin : RMII_RXER_Pin */
  GPIO_InitStruct.Pin = RMII_RXER_Pin;
  GPIO_InitStruct.Mode = GPIO_MODE_INPUT;
  GPIO_InitStruct.Pull = GPIO_NOPULL;
  HAL_GPIO_Init(RMII_RXER_GPIO_Port, &GPIO_InitStruct);

  /*Configure GPIO pins : RMII_REF_CLK_Pin RMII_MDIO_Pin RMII_CRS_DV_Pin */
  GPIO_InitStruct.Pin = RMII_REF_CLK_Pin|RMII_MDIO_Pin|RMII_CRS_DV_Pin;
  GPIO_InitStruct.Mode = GPIO_MODE_AF_PP;
  GPIO_InitStruct.Pull = GPIO_NOPULL;
  GPIO_InitStruct.Speed = GPIO_SPEED_FREQ_VERY_HIGH;
  GPIO_InitStruct.Alternate = GPIO_AF11_ETH;
  HAL_GPIO_Init(GPIOA, &GPIO_InitStruct);

  /*Configure GPIO pin : PA0 */
  GPIO_InitStruct.Pin = GPIO_PIN_0;
  GPIO_InitStruct.Mode = GPIO_MODE_ANALOG;
  GPIO_InitStruct.Pull = GPIO_NOPULL;
  HAL_GPIO_Init(GPIOA, &GPIO_InitStruct);

  /*Configure GPIO pins : DCMI_HSYNC_Pin PA6 */
  GPIO_InitStruct.Pin = DCMI_HSYNC_Pin|GPIO_PIN_6;
  GPIO_InitStruct.Mode = GPIO_MODE_AF_PP;
  GPIO_InitStruct.Pull = GPIO_NOPULL;
  GPIO_InitStruct.Speed = GPIO_SPEED_FREQ_LOW;
  GPIO_InitStruct.Alternate = GPIO_AF13_DCMI;
  HAL_GPIO_Init(GPIOA, &GPIO_InitStruct);

  /*Configure GPIO pins : ULPI_CLK_Pin ULPI_D0_Pin */
  GPIO_InitStruct.Pin = ULPI_CLK_Pin|ULPI_D0_Pin;
  GPIO_InitStruct.Mode = GPIO_MODE_AF_PP;
  GPIO_InitStruct.Pull = GPIO_NOPULL;
  GPIO_InitStruct.Speed = GPIO_SPEED_FREQ_VERY_HIGH;
  GPIO_InitStruct.Alternate = GPIO_AF10_OTG_HS;
  HAL_GPIO_Init(GPIOA, &GPIO_InitStruct);

  /*Configure GPIO pin : EBUZZ_M_Pin */
  GPIO_InitStruct.Pin = EBUZZ_M_Pin;
  GPIO_InitStruct.Mode = GPIO_MODE_OUTPUT_PP;
  GPIO_InitStruct.Pull = GPIO_NOPULL;
  GPIO_InitStruct.Speed = GPIO_SPEED_FREQ_LOW;
  HAL_GPIO_Init(EBUZZ_M_GPIO_Port, &GPIO_InitStruct);

  /*Configure GPIO pin : EBUZZ_P_Pin */
  GPIO_InitStruct.Pin = EBUZZ_P_Pin;
  GPIO_InitStruct.Mode = GPIO_MODE_OUTPUT_PP;
  GPIO_InitStruct.Pull = GPIO_NOPULL;
  GPIO_InitStruct.Speed = GPIO_SPEED_FREQ_LOW;
  HAL_GPIO_Init(EBUZZ_P_GPIO_Port, &GPIO_InitStruct);

  /* EXTI interrupt init*/
  HAL_NVIC_SetPriority(EXTI0_IRQn, 0, 0);
  HAL_NVIC_EnableIRQ(EXTI0_IRQn);

  HAL_NVIC_SetPriority(EXTI1_IRQn, 0, 0);
  HAL_NVIC_EnableIRQ(EXTI1_IRQn);

  HAL_NVIC_SetPriority(EXTI2_IRQn, 0, 0);
  HAL_NVIC_EnableIRQ(EXTI2_IRQn);

  HAL_NVIC_SetPriority(EXTI3_IRQn, 0, 0);
  HAL_NVIC_EnableIRQ(EXTI3_IRQn);

  HAL_NVIC_SetPriority(EXTI4_IRQn, 0, 0);
  HAL_NVIC_EnableIRQ(EXTI4_IRQn);

  HAL_NVIC_SetPriority(EXTI9_5_IRQn, 0, 0);
  HAL_NVIC_EnableIRQ(EXTI9_5_IRQn);

  HAL_NVIC_SetPriority(EXTI15_10_IRQn, 0, 0);
  HAL_NVIC_EnableIRQ(EXTI15_10_IRQn);

}

 /**
  * @brief  Period elapsed callback in non blocking mode
  * @note   This function is called  when TIM6 interrupt took place, inside
  * HAL_TIM_IRQHandler(). It makes a direct call to HAL_IncTick() to increment
  * a global variable "uwTick" used as application time base.
  * @param  htim : TIM handle
  * @retval None
  */
void HAL_TIM_PeriodElapsedCallback(TIM_HandleTypeDef *htim)
{
  if (htim->Instance == TIM6) {
    HAL_IncTick();
  }
}

void Error_Handler(void)
{
}

/************************ (C) COPYRIGHT STMicroelectronics *****END OF FILE****/
